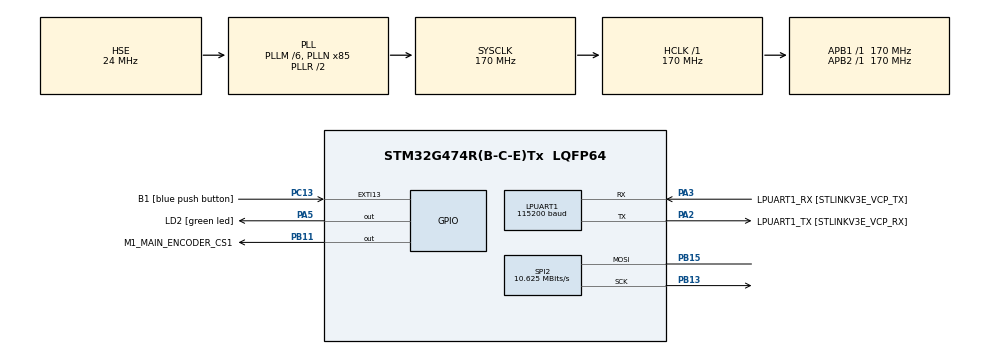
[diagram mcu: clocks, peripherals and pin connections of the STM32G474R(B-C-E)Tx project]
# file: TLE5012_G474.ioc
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FREERTOS.Tasks01=defaultTask,0,128,StartDefaultTask,Default,NULL,Dynamic,NULL,NULL;myTask02,-3,128,StartTask02,Default,NULL,Dynamic,NULL,NULL
LPUART1.BaudRate=115200
LPUART1.WordLength=UART_WORDLENGTH_8B
Mcu.Family=STM32G4
Mcu.Name=STM32G474R(B-C-E)Tx
Mcu.Package=LQFP64
NVIC.EXTI15_10_IRQn=true\:5\:0\:false\:false\:true\:true\:true\:true
NVIC.PriorityGroup=NVIC_PRIORITYGROUP_4
NVIC.TIM6_DAC_IRQn=true\:15\:0\:false\:false\:true\:false\:false\:true
NVIC.TimeBase=TIM6_DAC_IRQn
NVIC.TimeBaseIP=TIM6
PA13.GPIO_Label=T_SWDIO
PA13.Mode=Serial_Wire
PA13.Signal=SYS_JTMS-SWDIO
PA14.GPIO_Label=T_SWCLK
PA14.Mode=Serial_Wire
PA14.Signal=SYS_JTCK-SWCLK
PA2.GPIO_Label=LPUART1_TX [STLINKV3E_VCP_RX]
PA2.Mode=Asynchronous
PA2.Signal=LPUART1_TX
PA3.GPIO_Label=LPUART1_RX [STLINKV3E_VCP_TX]
PA3.Mode=Asynchronous
PA3.Signal=LPUART1_RX
PA5.GPIO_Label=LD2 [green led]
PA5.Signal=GPIO_Output
PB11.GPIO_Label=M1_MAIN_ENCODER_CS1
PB11.GPIO_PuPd=GPIO_PULLUP
PB11.GPIO_Speed=GPIO_SPEED_FREQ_HIGH
PB11.PinState=GPIO_PIN_SET
PB11.Signal=GPIO_Output
PB13.GPIO_PuPd=GPIO_PULLDOWN
PB13.GPIO_Speed=GPIO_SPEED_FREQ_HIGH
PB13.Mode=Simplex_Bidirectional_Master
PB13.Signal=SPI2_SCK
PB15.GPIO_Speed=GPIO_SPEED_FREQ_HIGH
PB15.Mode=Simplex_Bidirectional_Master
PB15.Signal=SPI2_MOSI
PB3.GPIO_Label=T_SWO
PB3.Signal=SYS_JTDO-SWO
PC13.GPIO_Label=B1 [blue push button]
PC13.Signal=GPXTI13
PC14-OSC32_IN.Mode=LSE-External-Oscillator
PC14-OSC32_IN.Signal=RCC_OSC32_IN
PC15-OSC32_OUT.Mode=LSE-External-Oscillator
PC15-OSC32_OUT.Signal=RCC_OSC32_OUT
PF0-OSC_IN.Mode=HSE-External-Oscillator
PF0-OSC_IN.Signal=RCC_OSC_IN
PF1-OSC_OUT.Mode=HSE-External-Oscillator
PF1-OSC_OUT.Signal=RCC_OSC_OUT
ProjectManager.HeapSize=0x200
ProjectManager.StackSize=0x400
ProjectManager.TargetToolchain=MDK-ARM V5.32
RCC.ADC12Freq_Value=170000000
RCC.ADC345Freq_Value=170000000
RCC.AHBFreq_Value=170000000
RCC.APB1Freq_Value=170000000
RCC.APB1TimFreq_Value=170000000
RCC.APB2Freq_Value=170000000
RCC.APB2TimFreq_Value=170000000
RCC.CortexFreq_Value=170000000
RCC.EXTERNAL_CLOCK_VALUE=12288000
RCC.EnbaleCSS=true
RCC.HCLKFreq_Value=170000000
RCC.HSE_VALUE=24000000
RCC.HSI48_VALUE=48000000
RCC.HSI_VALUE=16000000
RCC.PLLM=RCC_PLLM_DIV6
RCC.PLLN=85
RCC.PLLSourceVirtual=RCC_PLLSOURCE_HSE
RCC.RTCClockSelection=RCC_RTCCLKSOURCE_LSE
RCC.SYSCLKFreq_VALUE=170000000
RCC.SYSCLKSource=RCC_SYSCLKSOURCE_PLLCLK
RCC.USBFreq_Value=170000000
RCC.VCOOutputFreq_Value=340000000
SPI2.BaudRatePrescaler=SPI_BAUDRATEPRESCALER_16
SPI2.CLKPhase=SPI_PHASE_2EDGE
SPI2.CalculateBaudRate=10.625 MBits/s
SPI2.DataSize=SPI_DATASIZE_16BIT
SPI2.Direction=SPI_DIRECTION_1LINE
SPI2.Mode=SPI_MODE_MASTER
SPI2.VirtualType=VM_MASTER
VP_FREERTOS_VS_CMSIS_V1.Mode=CMSIS_V1
VP_SYS_VS_DBSignals.Mode=DisableDeadBatterySignals
VP_SYS_VS_tim6.Mode=TIM6
board=NUCLEO-G474RE

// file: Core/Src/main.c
/* USER CODE BEGIN Header */
/**
  ******************************************************************************
  * @file           : main.c
  * @brief          : Main program body
  ******************************************************************************
  * @attention
  *
  * <h2><center>&copy; Copyright (c) 2021 STMicroelectronics.
  * All rights reserved.</center></h2>
  *
  * This software component is licensed by ST under Ultimate Liberty license
  * SLA0044, the "License"; You may not use this file except in compliance with
  * the License. You may obtain a copy of the License at:
  *                             www.st.com/SLA0044
  *
  ******************************************************************************
  */
/* USER CODE END Header */
#include "main.h"
#include "cmsis_os.h"

/* USER CODE BEGIN Includes */
#include "tle5012b_drive.h"

/* USER CODE END Includes */

UART_HandleTypeDef hlpuart1;

SPI_HandleTypeDef hspi2;

osThreadId defaultTaskHandle;
osThreadId myTask02Handle;
/* USER CODE BEGIN PV */
uint16_t ang;

/* USER CODE END PV */

void SystemClock_Config(void);
static void MX_GPIO_Init(void);
static void MX_LPUART1_UART_Init(void);
static void MX_SPI2_Init(void);
void StartDefaultTask(void const * argument);
void StartTask02(void const * argument);

int main(void)
{

  /* MCU Configuration--------------------------------------------------------*/

  /* Reset of all peripherals, Initializes the Flash interface and the Systick. */
  HAL_Init();

  /* Configure the system clock */
  SystemClock_Config();

  /* Initialize all configured peripherals */
  MX_GPIO_Init();
  MX_LPUART1_UART_Init();
  MX_SPI2_Init();
  /* USER CODE BEGIN 2 */
  TLE5012_Init( &Abs_TLE5012_M1 );
  /* USER CODE END 2 */

  /* Create the thread(s) */
  /* definition and creation of defaultTask */
  osThreadDef(defaultTask, StartDefaultTask, osPriorityNormal, 0, 128);
  defaultTaskHandle = osThreadCreate(osThread(defaultTask), NULL);

  /* definition and creation of myTask02 */
  osThreadDef(myTask02, StartTask02, osPriorityIdle, 0, 128);
  myTask02Handle = osThreadCreate(osThread(myTask02), NULL);

  /* Start scheduler */
  osKernelStart();

  /* We should never get here as control is now taken by the scheduler */
  /* Infinite loop */
  while (1)
  {

  }
}

void SystemClock_Config(void)
{
  RCC_OscInitTypeDef RCC_OscInitStruct = {0};
  RCC_ClkInitTypeDef RCC_ClkInitStruct = {0};
  RCC_PeriphCLKInitTypeDef PeriphClkInit = {0};

  /** Configure the main internal regulator output voltage
  */
  HAL_PWREx_ControlVoltageScaling(PWR_REGULATOR_VOLTAGE_SCALE1_BOOST);
  /** Initializes the RCC Oscillators according to the specified parameters
  * in the RCC_OscInitTypeDef structure.
  */
  RCC_OscInitStruct.OscillatorType = RCC_OSCILLATORTYPE_HSE;
  RCC_OscInitStruct.HSEState = RCC_HSE_ON;
  RCC_OscInitStruct.PLL.PLLState = RCC_PLL_ON;
  RCC_OscInitStruct.PLL.PLLSource = RCC_PLLSOURCE_HSE;
  RCC_OscInitStruct.PLL.PLLM = RCC_PLLM_DIV6;
  RCC_OscInitStruct.PLL.PLLN = 85;
  RCC_OscInitStruct.PLL.PLLP = RCC_PLLP_DIV2;
  RCC_OscInitStruct.PLL.PLLQ = RCC_PLLQ_DIV2;
  RCC_OscInitStruct.PLL.PLLR = RCC_PLLR_DIV2;
  if (HAL_RCC_OscConfig(&RCC_OscInitStruct) != HAL_OK)
  {
    Error_Handler();
  }
  /** Initializes the CPU, AHB and APB buses clocks
  */
  RCC_ClkInitStruct.ClockType = RCC_CLOCKTYPE_HCLK|RCC_CLOCKTYPE_SYSCLK
                              |RCC_CLOCKTYPE_PCLK1|RCC_CLOCKTYPE_PCLK2;
  RCC_ClkInitStruct.SYSCLKSource = RCC_SYSCLKSOURCE_PLLCLK;
  RCC_ClkInitStruct.AHBCLKDivider = RCC_SYSCLK_DIV1;
  RCC_ClkInitStruct.APB1CLKDivider = RCC_HCLK_DIV1;
  RCC_ClkInitStruct.APB2CLKDivider = RCC_HCLK_DIV1;

  if (HAL_RCC_ClockConfig(&RCC_ClkInitStruct, FLASH_LATENCY_4) != HAL_OK)
  {
    Error_Handler();
  }
  /** Initializes the peripherals clocks
  */
  PeriphClkInit.PeriphClockSelection = RCC_PERIPHCLK_LPUART1;
  PeriphClkInit.Lpuart1ClockSelection = RCC_LPUART1CLKSOURCE_PCLK1;
  if (HAL_RCCEx_PeriphCLKConfig(&PeriphClkInit) != HAL_OK)
  {
    Error_Handler();
  }
  /** Enables the Clock Security System
  */
  HAL_RCC_EnableCSS();
}

static void MX_LPUART1_UART_Init(void)
{

  hlpuart1.Instance = LPUART1;
  hlpuart1.Init.BaudRate = 115200;
  hlpuart1.Init.WordLength = UART_WORDLENGTH_8B;
  hlpuart1.Init.StopBits = UART_STOPBITS_1;
  hlpuart1.Init.Parity = UART_PARITY_NONE;
  hlpuart1.Init.Mode = UART_MODE_TX_RX;
  hlpuart1.Init.HwFlowCtl = UART_HWCONTROL_NONE;
  hlpuart1.Init.OneBitSampling = UART_ONE_BIT_SAMPLE_DISABLE;
  hlpuart1.Init.ClockPrescaler = UART_PRESCALER_DIV1;
  hlpuart1.AdvancedInit.AdvFeatureInit = UART_ADVFEATURE_NO_INIT;
  if (HAL_UART_Init(&hlpuart1) != HAL_OK)
  {
    Error_Handler();
  }
  if (HAL_UARTEx_SetTxFifoThreshold(&hlpuart1, UART_TXFIFO_THRESHOLD_1_8) != HAL_OK)
  {
    Error_Handler();
  }
  if (HAL_UARTEx_SetRxFifoThreshold(&hlpuart1, UART_RXFIFO_THRESHOLD_1_8) != HAL_OK)
  {
    Error_Handler();
  }
  if (HAL_UARTEx_DisableFifoMode(&hlpuart1) != HAL_OK)
  {
    Error_Handler();
  }

}

static void MX_SPI2_Init(void)
{

  /* SPI2 parameter configuration*/
  hspi2.Instance = SPI2;
  hspi2.Init.Mode = SPI_MODE_MASTER;
  hspi2.Init.Direction = SPI_DIRECTION_1LINE;
  hspi2.Init.DataSize = SPI_DATASIZE_16BIT;
  hspi2.Init.CLKPolarity = SPI_POLARITY_LOW;
  hspi2.Init.CLKPhase = SPI_PHASE_2EDGE;
  hspi2.Init.NSS = SPI_NSS_SOFT;
  hspi2.Init.BaudRatePrescaler = SPI_BAUDRATEPRESCALER_16;
  hspi2.Init.FirstBit = SPI_FIRSTBIT_MSB;
  hspi2.Init.TIMode = SPI_TIMODE_DISABLE;
  hspi2.Init.CRCCalculation = SPI_CRCCALCULATION_DISABLE;
  hspi2.Init.CRCPolynomial = 7;
  hspi2.Init.CRCLength = SPI_CRC_LENGTH_DATASIZE;
  hspi2.Init.NSSPMode = SPI_NSS_PULSE_DISABLE;
  if (HAL_SPI_Init(&hspi2) != HAL_OK)
  {
    Error_Handler();
  }

}

static void MX_GPIO_Init(void)
{
  GPIO_InitTypeDef GPIO_InitStruct = {0};

  /* GPIO Ports Clock Enable */
  __HAL_RCC_GPIOC_CLK_ENABLE();
  __HAL_RCC_GPIOF_CLK_ENABLE();
  __HAL_RCC_GPIOA_CLK_ENABLE();
  __HAL_RCC_GPIOB_CLK_ENABLE();

  /*Configure GPIO pin Output Level */
  HAL_GPIO_WritePin(LD2_GPIO_Port, LD2_Pin, GPIO_PIN_RESET);

  /*Configure GPIO pin Output Level */
  HAL_GPIO_WritePin(M1_MAIN_ENCODER_CS1_GPIO_Port, M1_MAIN_ENCODER_CS1_Pin, GPIO_PIN_SET);

  /*Configure GPIO pin : B1_Pin */
  GPIO_InitStruct.Pin = B1_Pin;
  GPIO_InitStruct.Mode = GPIO_MODE_IT_RISING;
  GPIO_InitStruct.Pull = GPIO_NOPULL;
  HAL_GPIO_Init(B1_GPIO_Port, &GPIO_InitStruct);

  /*Configure GPIO pin : LD2_Pin */
  GPIO_InitStruct.Pin = LD2_Pin;
  GPIO_InitStruct.Mode = GPIO_MODE_OUTPUT_PP;
  GPIO_InitStruct.Pull = GPIO_NOPULL;
  GPIO_InitStruct.Speed = GPIO_SPEED_FREQ_LOW;
  HAL_GPIO_Init(LD2_GPIO_Port, &GPIO_InitStruct);

  /*Configure GPIO pin : M1_MAIN_ENCODER_CS1_Pin */
  GPIO_InitStruct.Pin = M1_MAIN_ENCODER_CS1_Pin;
  GPIO_InitStruct.Mode = GPIO_MODE_OUTPUT_PP;
  GPIO_InitStruct.Pull = GPIO_PULLUP;
  GPIO_InitStruct.Speed = GPIO_SPEED_FREQ_HIGH;
  HAL_GPIO_Init(M1_MAIN_ENCODER_CS1_GPIO_Port, &GPIO_InitStruct);

  /* EXTI interrupt init*/
  HAL_NVIC_SetPriority(EXTI15_10_IRQn, 5, 0);
  HAL_NVIC_EnableIRQ(EXTI15_10_IRQn);

}

void StartDefaultTask(void const * argument)
{
  for(;;)
  {
    osDelay(1);
  }
}

void StartTask02(void const * argument)
{
  /* USER CODE BEGIN StartTask02 */
  /* Infinite loop */
  for(;;)
  {
    osDelay(1);
    TLE5012_read_angle( &Abs_TLE5012_M1, &ang );

  }
  /* USER CODE END StartTask02 */
}

void HAL_TIM_PeriodElapsedCallback(TIM_HandleTypeDef *htim)
{
  if (htim->Instance == TIM6) {
    HAL_IncTick();
  }
}

void Error_Handler(void)
{
  __disable_irq();
  while (1)
  {
  }
}

/************************ (C) COPYRIGHT STMicroelectronics *****END OF FILE****/
